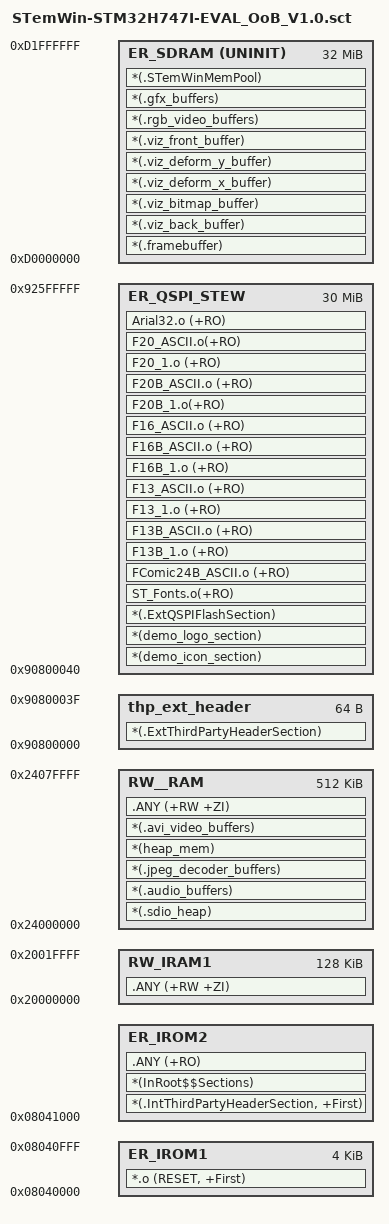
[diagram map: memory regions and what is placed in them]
; *************************************************************
; *** Scatter-Loading Description File generated by uVision ***
; *************************************************************

LR_IROM1 0x08040000 0x00001000  {    ; load region size_region
  ER_IROM1 0x08040000 0x00001000  {  ; load address = execution address
   *.o (RESET, +First)
  }
  RW_IRAM1 0x20000000 0x00020000  {  ; RW data
		.ANY (+RW +ZI)
	}
}
LR_IROM2 0x08041000     {    ; load region size_region
	ER_IROM2 0x08041000     {
		*(.IntThirdPartyHeaderSection, +First)
		*(InRoot$$Sections)
		.ANY (+RO) 
	}
	RW__RAM  0x24000000 0x80000{
		*(.sdio_heap)
		*(.audio_buffers)
		*(.jpeg_decoder_buffers)
		*(heap_mem)
		*(.avi_video_buffers)
		.ANY (+RW +ZI)
	}
	ER_SDRAM 0xD0000000 UNINIT 0x2000000{ 
		*(.framebuffer)
		*(.viz_back_buffer)
		*(.viz_bitmap_buffer)
		*(.viz_deform_x_buffer)
		*(.viz_deform_y_buffer)
		*(.viz_front_buffer)
		*(.rgb_video_buffers)
		*(.gfx_buffers)
		*(.STemWinMemPool)
	} 
}
LR_QSPI_STEW 0x90800000  {
	thp_ext_header  0x90800000  0x40 { 
		*(.ExtThirdPartyHeaderSection)   
	}
	ER_QSPI_STEW  0x90800040 0x1DFFFC0 {
		*(demo_icon_section)
		*(demo_logo_section)
		*(.ExtQSPIFlashSection)
		ST_Fonts.o(+RO)
		FComic24B_ASCII.o (+RO)
		F13B_1.o (+RO)
		F13B_ASCII.o (+RO)
		F13_1.o (+RO)
		F13_ASCII.o (+RO)
		F16B_1.o (+RO)
		F16B_ASCII.o (+RO)
		F16_ASCII.o (+RO)
		F20B_1.o(+RO)
		F20B_ASCII.o (+RO)
		F20_1.o (+RO)
		F20_ASCII.o(+RO)
		Arial32.o (+RO) 
	}
}
